AUTOSAR XML (schema 4-2-2)
package /UAES/ASW
  swc implementation Implementation: programming-language=C, sw-version=1.30.1, used-code-generator=Embedded Coder 7.1 (R2018b) 24-May-2018, vendor-id=0, behavior=InternalBehavior
    code-descriptors:
      code Code
        artifact-descriptors:
          short-label=IntLamp_Ctrl_c, category=SWSRC
          short-label=IntLamp_Ctrl_h, category=SWHDR
          short-label=rtwtypes_h, category=SWHDR
    resource consumption RsrcCons_IntLamp_Ctrl
package /UAES/ASW/SwComponentTypes
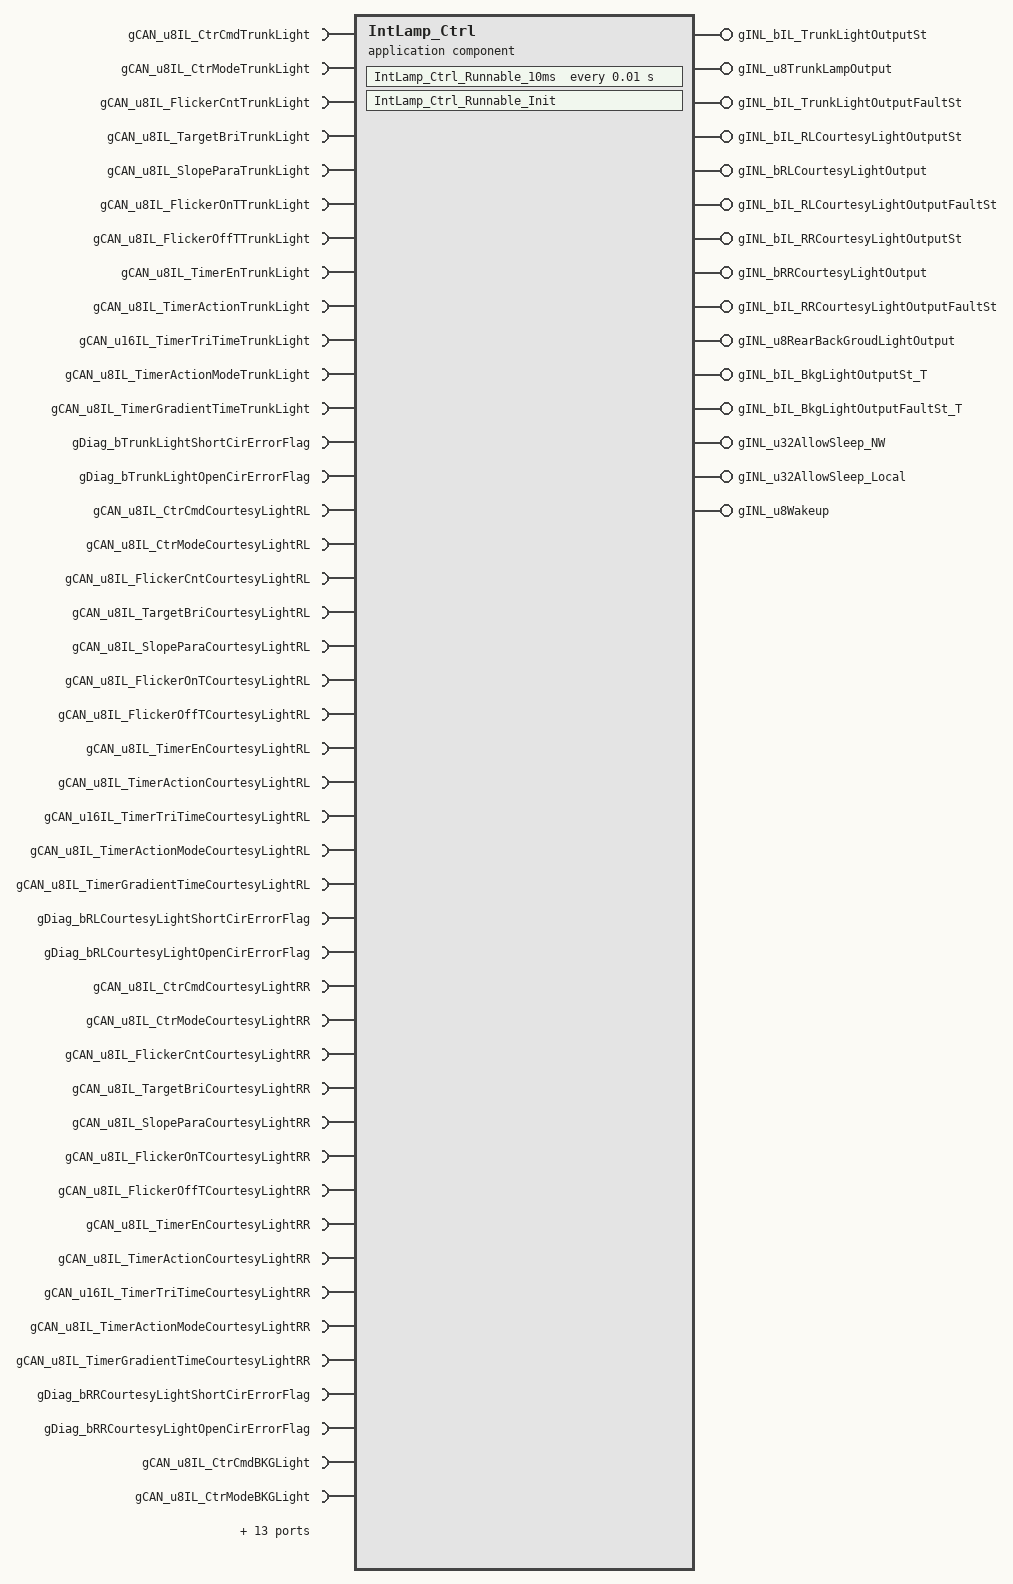
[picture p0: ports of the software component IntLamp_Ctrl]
  application sw component type IntLamp_Ctrl
    57 x require port:
      gCAN_u8IL_CtrCmdTrunkLight: nonqueued-receiver-com-spec{data-element=gCAN_u8IL_CtrCmdTrunkLight/Val, init-value=0}, required-interface=gCAN_u8IL_CtrCmdTrunkLight
      gCAN_u8IL_CtrModeTrunkLight: nonqueued-receiver-com-spec{data-element=gCAN_u8IL_CtrModeTrunkLight/Val, init-value=0}, required-interface=gCAN_u8IL_CtrModeTrunkLight
      gCAN_u8IL_FlickerCntTrunkLight: nonqueued-receiver-com-spec{data-element=gCAN_u8IL_FlickerCntTrunkLight/Val, init-value=0}, required-interface=gCAN_u8IL_FlickerCntTrunkLight
      gCAN_u8IL_TargetBriTrunkLight: nonqueued-receiver-com-spec{data-element=gCAN_u8IL_TargetBriTrunkLight/Val, init-value=0}, required-interface=gCAN_u8IL_TargetBriTrunkLight
      gCAN_u8IL_SlopeParaTrunkLight: nonqueued-receiver-com-spec{data-element=gCAN_u8IL_SlopeParaTrunkLight/Val, init-value=0}, required-interface=gCAN_u8IL_SlopeParaTrunkLight
      gCAN_u8IL_FlickerOnTTrunkLight: nonqueued-receiver-com-spec{data-element=gCAN_u8IL_FlickerOnTTrunkLight/Val, init-value=0}, required-interface=gCAN_u8IL_FlickerOnTTrunkLight
      gCAN_u8IL_FlickerOffTTrunkLight: nonqueued-receiver-com-spec{data-element=gCAN_u8IL_FlickerOffTTrunkLight/Val, init-value=0}, required-interface=gCAN_u8IL_FlickerOffTTrunkLight
      gCAN_u8IL_TimerEnTrunkLight: nonqueued-receiver-com-spec{data-element=gCAN_u8IL_TimerEnTrunkLight/Val, init-value=0}, required-interface=gCAN_u8IL_TimerEnTrunkLight
      gCAN_u8IL_TimerActionTrunkLight: nonqueued-receiver-com-spec{data-element=gCAN_u8IL_TimerActionTrunkLight/Val, init-value=0}, required-interface=gCAN_u8IL_TimerActionTrunkLight
      gCAN_u16IL_TimerTriTimeTrunkLight: nonqueued-receiver-com-spec{data-element=gCAN_u16IL_TimerTriTimeTrunkLight/Val, init-value=0}, required-interface=gCAN_u16IL_TimerTriTimeTrunkLight
      gCAN_u8IL_TimerActionModeTrunkLight: nonqueued-receiver-com-spec{data-element=gCAN_u8IL_TimerActionModeTrunkLight/Val, init-value=0}, required-interface=gCAN_u8IL_TimerActionModeTrunkLight
      gCAN_u8IL_TimerGradientTimeTrunkLight: nonqueued-receiver-com-spec{data-element=gCAN_u8IL_TimerGradientTimeTrunkLight/Val, init-value=0}, required-interface=gCAN_u8IL_TimerGradientTimeTrunkLight
      gDiag_bTrunkLightShortCirErrorFlag: nonqueued-receiver-com-spec{data-element=gDiag_bTrunkLightShortCirErrorFlag/Val, init-value=0}, required-interface=gDiag_bTrunkLightShortCirErrorFlag
      gDiag_bTrunkLightOpenCirErrorFlag: nonqueued-receiver-com-spec{data-element=gDiag_bTrunkLightOpenCirErrorFlag/Val, init-value=0}, required-interface=gDiag_bTrunkLightOpenCirErrorFlag
      gCAN_u8IL_CtrCmdCourtesyLightRL: nonqueued-receiver-com-spec{data-element=gCAN_u8IL_CtrCmdCourtesyLightRL/Val, init-value=0}, required-interface=gCAN_u8IL_CtrCmdCourtesyLightRL
      gCAN_u8IL_CtrModeCourtesyLightRL: nonqueued-receiver-com-spec{data-element=gCAN_u8IL_CtrModeCourtesyLightRL/Val, init-value=0}, required-interface=gCAN_u8IL_CtrModeCourtesyLightRL
      gCAN_u8IL_FlickerCntCourtesyLightRL: nonqueued-receiver-com-spec{data-element=gCAN_u8IL_FlickerCntCourtesyLightRL/Val, init-value=0}, required-interface=gCAN_u8IL_FlickerCntCourtesyLightRL
      gCAN_u8IL_TargetBriCourtesyLightRL: nonqueued-receiver-com-spec{data-element=gCAN_u8IL_TargetBriCourtesyLightRL/Val, init-value=0}, required-interface=gCAN_u8IL_TargetBriCourtesyLightRL
      gCAN_u8IL_SlopeParaCourtesyLightRL: nonqueued-receiver-com-spec{data-element=gCAN_u8IL_SlopeParaCourtesyLightRL/Val, init-value=0}, required-interface=gCAN_u8IL_SlopeParaCourtesyLightRL
      gCAN_u8IL_FlickerOnTCourtesyLightRL: nonqueued-receiver-com-spec{data-element=gCAN_u8IL_FlickerOnTCourtesyLightRL/Val, init-value=0}, required-interface=gCAN_u8IL_FlickerOnTCourtesyLightRL
      gCAN_u8IL_FlickerOffTCourtesyLightRL: nonqueued-receiver-com-spec{data-element=gCAN_u8IL_FlickerOffTCourtesyLightRL/Val, init-value=0}, required-interface=gCAN_u8IL_FlickerOffTCourtesyLightRL
      gCAN_u8IL_TimerEnCourtesyLightRL: nonqueued-receiver-com-spec{data-element=gCAN_u8IL_TimerEnCourtesyLightRL/Val, init-value=0}, required-interface=gCAN_u8IL_TimerEnCourtesyLightRL
      gCAN_u8IL_TimerActionCourtesyLightRL: nonqueued-receiver-com-spec{data-element=gCAN_u8IL_TimerActionCourtesyLightRL/Val, init-value=0}, required-interface=gCAN_u8IL_TimerActionCourtesyLightRL
      gCAN_u16IL_TimerTriTimeCourtesyLightRL: nonqueued-receiver-com-spec{data-element=gCAN_u16IL_TimerTriTimeCourtesyLightRL/Val, init-value=0}, required-interface=gCAN_u16IL_TimerTriTimeCourtesyLightRL
      gCAN_u8IL_TimerActionModeCourtesyLightRL: nonqueued-receiver-com-spec{data-element=gCAN_u8IL_TimerActionModeCourtesyLightRL/Val, init-value=0}, required-interface=gCAN_u8IL_TimerActionModeCourtesyLightRL
      gCAN_u8IL_TimerGradientTimeCourtesyLightRL: nonqueued-receiver-com-spec{data-element=gCAN_u8IL_TimerGradientTimeCourtesyLightRL/Val, init-value=0}, required-interface=gCAN_u8IL_TimerGradientTimeCourtesyLightRL
      gDiag_bRLCourtesyLightShortCirErrorFlag: nonqueued-receiver-com-spec{data-element=gDiag_bRLCourtesyLightShortCirErrorFlag/Val, init-value=0}, required-interface=gDiag_bRLCourtesyLightShortCirErrorFlag
      gDiag_bRLCourtesyLightOpenCirErrorFlag: nonqueued-receiver-com-spec{data-element=gDiag_bRLCourtesyLightOpenCirErrorFlag/Val, init-value=0}, required-interface=gDiag_bRLCourtesyLightOpenCirErrorFlag
      gCAN_u8IL_CtrCmdCourtesyLightRR: nonqueued-receiver-com-spec{data-element=gCAN_u8IL_CtrCmdCourtesyLightRR/Val, init-value=0}, required-interface=gCAN_u8IL_CtrCmdCourtesyLightRR
      gCAN_u8IL_CtrModeCourtesyLightRR: nonqueued-receiver-com-spec{data-element=gCAN_u8IL_CtrModeCourtesyLightRR/Val, init-value=0}, required-interface=gCAN_u8IL_CtrModeCourtesyLightRR
      gCAN_u8IL_FlickerCntCourtesyLightRR: nonqueued-receiver-com-spec{data-element=gCAN_u8IL_FlickerCntCourtesyLightRR/Val, init-value=0}, required-interface=gCAN_u8IL_FlickerCntCourtesyLightRR
      gCAN_u8IL_TargetBriCourtesyLightRR: nonqueued-receiver-com-spec{data-element=gCAN_u8IL_TargetBriCourtesyLightRR/Val, init-value=0}, required-interface=gCAN_u8IL_TargetBriCourtesyLightRR
      gCAN_u8IL_SlopeParaCourtesyLightRR: nonqueued-receiver-com-spec{data-element=gCAN_u8IL_SlopeParaCourtesyLightRR/Val, init-value=0}, required-interface=gCAN_u8IL_SlopeParaCourtesyLightRR
      gCAN_u8IL_FlickerOnTCourtesyLightRR: nonqueued-receiver-com-spec{data-element=gCAN_u8IL_FlickerOnTCourtesyLightRR/Val, init-value=0}, required-interface=gCAN_u8IL_FlickerOnTCourtesyLightRR
      gCAN_u8IL_FlickerOffTCourtesyLightRR: nonqueued-receiver-com-spec{data-element=gCAN_u8IL_FlickerOffTCourtesyLightRR/Val, init-value=0}, required-interface=gCAN_u8IL_FlickerOffTCourtesyLightRR
      gCAN_u8IL_TimerEnCourtesyLightRR: nonqueued-receiver-com-spec{data-element=gCAN_u8IL_TimerEnCourtesyLightRR/Val, init-value=0}, required-interface=gCAN_u8IL_TimerEnCourtesyLightRR
      gCAN_u8IL_TimerActionCourtesyLightRR: nonqueued-receiver-com-spec{data-element=gCAN_u8IL_TimerActionCourtesyLightRR/Val, init-value=0}, required-interface=gCAN_u8IL_TimerActionCourtesyLightRR
      gCAN_u16IL_TimerTriTimeCourtesyLightRR: nonqueued-receiver-com-spec{data-element=gCAN_u16IL_TimerTriTimeCourtesyLightRR/Val, init-value=0}, required-interface=gCAN_u16IL_TimerTriTimeCourtesyLightRR
      gCAN_u8IL_TimerActionModeCourtesyLightRR: nonqueued-receiver-com-spec{data-element=gCAN_u8IL_TimerActionModeCourtesyLightRR/Val, init-value=0}, required-interface=gCAN_u8IL_TimerActionModeCourtesyLightRR
      gCAN_u8IL_TimerGradientTimeCourtesyLightRR: nonqueued-receiver-com-spec{data-element=gCAN_u8IL_TimerGradientTimeCourtesyLightRR/Val, init-value=0}, required-interface=gCAN_u8IL_TimerGradientTimeCourtesyLightRR
      gDiag_bRRCourtesyLightShortCirErrorFlag: nonqueued-receiver-com-spec{data-element=gDiag_bRRCourtesyLightShortCirErrorFlag/Val, init-value=0}, required-interface=gDiag_bRRCourtesyLightShortCirErrorFlag
      gDiag_bRRCourtesyLightOpenCirErrorFlag: nonqueued-receiver-com-spec{data-element=gDiag_bRRCourtesyLightOpenCirErrorFlag/Val, init-value=0}, required-interface=gDiag_bRRCourtesyLightOpenCirErrorFlag
      gCAN_u8IL_CtrCmdBKGLight: nonqueued-receiver-com-spec{data-element=gCAN_u8IL_CtrCmdBKGLight/Val, init-value=0}, required-interface=gCAN_u8IL_CtrCmdBKGLight
      gCAN_u8IL_CtrModeBKGLight: nonqueued-receiver-com-spec{data-element=gCAN_u8IL_CtrModeBKGLight/Val, init-value=0}, required-interface=gCAN_u8IL_CtrModeBKGLight
      gCAN_u8IL_FlickerCntBKGLight: nonqueued-receiver-com-spec{data-element=gCAN_u8IL_FlickerCntBKGLight/Val, init-value=0}, required-interface=gCAN_u8IL_FlickerCntBKGLight
      gCAN_u8IL_TargetBriBKGLight: nonqueued-receiver-com-spec{data-element=gCAN_u8IL_TargetBriBKGLight/Val, init-value=0}, required-interface=gCAN_u8IL_TargetBriBKGLight
      gCAN_u8IL_SlopeParaBKGLight: nonqueued-receiver-com-spec{data-element=gCAN_u8IL_SlopeParaBKGLight/Val, init-value=0}, required-interface=gCAN_u8IL_SlopeParaBKGLight
      gCAN_u8IL_FlickerOnTBKGLight: nonqueued-receiver-com-spec{data-element=gCAN_u8IL_FlickerOnTBKGLight/Val, init-value=0}, required-interface=gCAN_u8IL_FlickerOnTBKGLight
      gCAN_u8IL_FlickerOffTBKGLight: nonqueued-receiver-com-spec{data-element=gCAN_u8IL_FlickerOffTBKGLight/Val, init-value=0}, required-interface=gCAN_u8IL_FlickerOffTBKGLight
      gCAN_u8IL_TimerEnBKGLight: nonqueued-receiver-com-spec{data-element=gCAN_u8IL_TimerEnBKGLight/Val, init-value=0}, required-interface=gCAN_u8IL_TimerEnBKGLight
      gCAN_u8IL_TimerActionBKGLight: nonqueued-receiver-com-spec{data-element=gCAN_u8IL_TimerActionBKGLight/Val, init-value=0}, required-interface=gCAN_u8IL_TimerActionBKGLight
      gCAN_u16IL_TimerTriTimeBKGLight: nonqueued-receiver-com-spec{data-element=gCAN_u16IL_TimerTriTimeBKGLight/Val, init-value=0}, required-interface=gCAN_u16IL_TimerTriTimeBKGLight
      gCAN_u8IL_TimerActionModeBKGLight: nonqueued-receiver-com-spec{data-element=gCAN_u8IL_TimerActionModeBKGLight/Val, init-value=0}, required-interface=gCAN_u8IL_TimerActionModeBKGLight
      gCAN_u8IL_TimerGradientTimeBKGLight: nonqueued-receiver-com-spec{data-element=gCAN_u8IL_TimerGradientTimeBKGLight/Val, init-value=0}, required-interface=gCAN_u8IL_TimerGradientTimeBKGLight
      gDiag_bReBkgLightPowerShortCirErrorFlag: nonqueued-receiver-com-spec{data-element=gDiag_bReBkgLightPowerShortCirErrorFlag/Val, init-value=0}, required-interface=gDiag_bReBkgLightPowerShortCirErrorFlag
      gDiag_bReBkgLightPowerOpenCirErrorFlag: nonqueued-receiver-com-spec{data-element=gDiag_bReBkgLightPowerOpenCirErrorFlag/Val, init-value=0}, required-interface=gDiag_bReBkgLightPowerOpenCirErrorFlag
      gASI_bIL_CtrCmdTrunkLight_TimeOut: nonqueued-receiver-com-spec{data-element=gASI_bIL_CtrCmdTrunkLight_TimeOut/Val, init-value=0}, required-interface=gASI_bIL_CtrCmdTrunkLight_TimeOut
    15 x provide port:
      gINL_bIL_TrunkLightOutputSt: nonqueued-sender-com-spec{data-element=gINL_bIL_TrunkLightOutputSt/Val, init-value=0}, provided-interface=gINL_bIL_TrunkLightOutputSt
      gINL_u8TrunkLampOutput: nonqueued-sender-com-spec{data-element=gINL_u8TrunkLampOutput/Val, init-value=0}, provided-interface=gINL_u8TrunkLampOutput
      gINL_bIL_TrunkLightOutputFaultSt: nonqueued-sender-com-spec{data-element=gINL_bIL_TrunkLightOutputFaultSt/Val, init-value=0}, provided-interface=gINL_bIL_TrunkLightOutputFaultSt
      gINL_bIL_RLCourtesyLightOutputSt: nonqueued-sender-com-spec{data-element=gINL_bIL_RLCourtesyLightOutputSt/Val, init-value=0}, provided-interface=gINL_bIL_RLCourtesyLightOutputSt
      gINL_bRLCourtesyLightOutput: nonqueued-sender-com-spec{data-element=gINL_bRLCourtesyLightOutput/Val, init-value=0}, provided-interface=gINL_bRLCourtesyLightOutput
      gINL_bIL_RLCourtesyLightOutputFaultSt: nonqueued-sender-com-spec{data-element=gINL_bIL_RLCourtesyLightOutputFaultSt/Val, init-value=0}, provided-interface=gINL_bIL_RLCourtesyLightOutputFaultSt
      gINL_bIL_RRCourtesyLightOutputSt: nonqueued-sender-com-spec{data-element=gINL_bIL_RRCourtesyLightOutputSt/Val, init-value=0}, provided-interface=gINL_bIL_RRCourtesyLightOutputSt
      gINL_bRRCourtesyLightOutput: nonqueued-sender-com-spec{data-element=gINL_bRRCourtesyLightOutput/Val, init-value=0}, provided-interface=gINL_bRRCourtesyLightOutput
      gINL_bIL_RRCourtesyLightOutputFaultSt: nonqueued-sender-com-spec{data-element=gINL_bIL_RRCourtesyLightOutputFaultSt/Val, init-value=0}, provided-interface=gINL_bIL_RRCourtesyLightOutputFaultSt
      gINL_u8RearBackGroudLightOutput: nonqueued-sender-com-spec{data-element=gINL_u8RearBackGroudLightOutput/Val, init-value=0}, provided-interface=gINL_u8RearBackGroudLightOutput
      gINL_bIL_BkgLightOutputSt_T: nonqueued-sender-com-spec{data-element=gINL_bIL_BkgLightOutputSt_T/Val, init-value=0}, provided-interface=gINL_bIL_BkgLightOutputSt_T
      gINL_bIL_BkgLightOutputFaultSt_T: nonqueued-sender-com-spec{data-element=gINL_bIL_BkgLightOutputFaultSt_T/Val, init-value=0}, provided-interface=gINL_bIL_BkgLightOutputFaultSt_T
      gINL_u32AllowSleep_NW: nonqueued-sender-com-spec{data-element=gINL_u32AllowSleep_NW/Val, init-value=0}, provided-interface=gINL_u32AllowSleep_NW
      gINL_u32AllowSleep_Local: nonqueued-sender-com-spec{data-element=gINL_u32AllowSleep_Local/Val, init-value=0}, provided-interface=gINL_u32AllowSleep_Local
      gINL_u8Wakeup: nonqueued-sender-com-spec{data-element=gINL_u8Wakeup/Val, init-value=0}, provided-interface=gINL_u8Wakeup
    behavior InternalBehavior: handle-termination-and-restart=NO-SUPPORT
      init event IntLamp_Ctrl_InitEvent: start-on-event=IntLamp_Ctrl_Runnable_Init
      timing event TMT_IntLamp_Ctrl_Runnable_10ms: start-on-event=IntLamp_Ctrl_Runnable_10ms, period=0.01
      runnable IntLamp_Ctrl_Runnable_Init
      runnable IntLamp_Ctrl_Runnable_10ms
        data-receive-point-by-arguments:
          57 x access:
            IN_gASI_bIL_CtrCmdTrunkLight_TimeOut_Val: accessed-variable=gASI_bIL_CtrCmdTrunkLight_TimeOut.Val
            IN_gCAN_u16IL_TimerTriTimeBKGLight_Val: accessed-variable=gCAN_u16IL_TimerTriTimeBKGLight.Val
            IN_gCAN_u16IL_TimerTriTimeCourtesyLightRL_Val: accessed-variable=gCAN_u16IL_TimerTriTimeCourtesyLightRL.Val
            IN_gCAN_u16IL_TimerTriTimeCourtesyLightRR_Val: accessed-variable=gCAN_u16IL_TimerTriTimeCourtesyLightRR.Val
            IN_gCAN_u16IL_TimerTriTimeTrunkLight_Val: accessed-variable=gCAN_u16IL_TimerTriTimeTrunkLight.Val
            IN_gCAN_u8IL_CtrCmdBKGLight_Val: accessed-variable=gCAN_u8IL_CtrCmdBKGLight.Val
            IN_gCAN_u8IL_CtrCmdCourtesyLightRL_Val: accessed-variable=gCAN_u8IL_CtrCmdCourtesyLightRL.Val
            IN_gCAN_u8IL_CtrCmdCourtesyLightRR_Val: accessed-variable=gCAN_u8IL_CtrCmdCourtesyLightRR.Val
            IN_gCAN_u8IL_CtrCmdTrunkLight_Val: accessed-variable=gCAN_u8IL_CtrCmdTrunkLight.Val
            IN_gCAN_u8IL_CtrModeBKGLight_Val: accessed-variable=gCAN_u8IL_CtrModeBKGLight.Val
            IN_gCAN_u8IL_CtrModeCourtesyLightRL_Val: accessed-variable=gCAN_u8IL_CtrModeCourtesyLightRL.Val
            IN_gCAN_u8IL_CtrModeCourtesyLightRR_Val: accessed-variable=gCAN_u8IL_CtrModeCourtesyLightRR.Val
            IN_gCAN_u8IL_CtrModeTrunkLight_Val: accessed-variable=gCAN_u8IL_CtrModeTrunkLight.Val
            IN_gCAN_u8IL_FlickerCntBKGLight_Val: accessed-variable=gCAN_u8IL_FlickerCntBKGLight.Val
            IN_gCAN_u8IL_FlickerCntCourtesyLightRL_Val: accessed-variable=gCAN_u8IL_FlickerCntCourtesyLightRL.Val
            IN_gCAN_u8IL_FlickerCntCourtesyLightRR_Val: accessed-variable=gCAN_u8IL_FlickerCntCourtesyLightRR.Val
            IN_gCAN_u8IL_FlickerCntTrunkLight_Val: accessed-variable=gCAN_u8IL_FlickerCntTrunkLight.Val
            IN_gCAN_u8IL_FlickerOffTBKGLight_Val: accessed-variable=gCAN_u8IL_FlickerOffTBKGLight.Val
            IN_gCAN_u8IL_FlickerOffTCourtesyLightRL_Val: accessed-variable=gCAN_u8IL_FlickerOffTCourtesyLightRL.Val
            IN_gCAN_u8IL_FlickerOffTCourtesyLightRR_Val: accessed-variable=gCAN_u8IL_FlickerOffTCourtesyLightRR.Val
            IN_gCAN_u8IL_FlickerOffTTrunkLight_Val: accessed-variable=gCAN_u8IL_FlickerOffTTrunkLight.Val
            IN_gCAN_u8IL_FlickerOnTBKGLight_Val: accessed-variable=gCAN_u8IL_FlickerOnTBKGLight.Val
            IN_gCAN_u8IL_FlickerOnTCourtesyLightRL_Val: accessed-variable=gCAN_u8IL_FlickerOnTCourtesyLightRL.Val
            IN_gCAN_u8IL_FlickerOnTCourtesyLightRR_Val: accessed-variable=gCAN_u8IL_FlickerOnTCourtesyLightRR.Val
            IN_gCAN_u8IL_FlickerOnTTrunkLight_Val: accessed-variable=gCAN_u8IL_FlickerOnTTrunkLight.Val
            IN_gCAN_u8IL_SlopeParaBKGLight_Val: accessed-variable=gCAN_u8IL_SlopeParaBKGLight.Val
            IN_gCAN_u8IL_SlopeParaCourtesyLightRL_Val: accessed-variable=gCAN_u8IL_SlopeParaCourtesyLightRL.Val
            IN_gCAN_u8IL_SlopeParaCourtesyLightRR_Val: accessed-variable=gCAN_u8IL_SlopeParaCourtesyLightRR.Val
            IN_gCAN_u8IL_SlopeParaTrunkLight_Val: accessed-variable=gCAN_u8IL_SlopeParaTrunkLight.Val
            IN_gCAN_u8IL_TargetBriBKGLight_Val: accessed-variable=gCAN_u8IL_TargetBriBKGLight.Val
            IN_gCAN_u8IL_TargetBriCourtesyLightRL_Val: accessed-variable=gCAN_u8IL_TargetBriCourtesyLightRL.Val
            IN_gCAN_u8IL_TargetBriCourtesyLightRR_Val: accessed-variable=gCAN_u8IL_TargetBriCourtesyLightRR.Val
            IN_gCAN_u8IL_TargetBriTrunkLight_Val: accessed-variable=gCAN_u8IL_TargetBriTrunkLight.Val
            IN_gCAN_u8IL_TimerActionBKGLight_Val: accessed-variable=gCAN_u8IL_TimerActionBKGLight.Val
            IN_gCAN_u8IL_TimerActionCourtesyLightRL_Val: accessed-variable=gCAN_u8IL_TimerActionCourtesyLightRL.Val
            IN_gCAN_u8IL_TimerActionCourtesyLightRR_Val: accessed-variable=gCAN_u8IL_TimerActionCourtesyLightRR.Val
            IN_gCAN_u8IL_TimerActionModeBKGLight_Val: accessed-variable=gCAN_u8IL_TimerActionModeBKGLight.Val
            IN_gCAN_u8IL_TimerActionModeCourtesyLightRL_Val: accessed-variable=gCAN_u8IL_TimerActionModeCourtesyLightRL.Val
            IN_gCAN_u8IL_TimerActionModeCourtesyLightRR_Val: accessed-variable=gCAN_u8IL_TimerActionModeCourtesyLightRR.Val
            IN_gCAN_u8IL_TimerActionModeTrunkLight_Val: accessed-variable=gCAN_u8IL_TimerActionModeTrunkLight.Val
            IN_gCAN_u8IL_TimerActionTrunkLight_Val: accessed-variable=gCAN_u8IL_TimerActionTrunkLight.Val
            IN_gCAN_u8IL_TimerEnBKGLight_Val: accessed-variable=gCAN_u8IL_TimerEnBKGLight.Val
            IN_gCAN_u8IL_TimerEnCourtesyLightRL_Val: accessed-variable=gCAN_u8IL_TimerEnCourtesyLightRL.Val
            IN_gCAN_u8IL_TimerEnCourtesyLightRR_Val: accessed-variable=gCAN_u8IL_TimerEnCourtesyLightRR.Val
            IN_gCAN_u8IL_TimerEnTrunkLight_Val: accessed-variable=gCAN_u8IL_TimerEnTrunkLight.Val
            IN_gCAN_u8IL_TimerGradientTimeBKGLight_Val: accessed-variable=gCAN_u8IL_TimerGradientTimeBKGLight.Val
            IN_gCAN_u8IL_TimerGradientTimeCourtesyLightRL_Val: accessed-variable=gCAN_u8IL_TimerGradientTimeCourtesyLightRL.Val
            IN_gCAN_u8IL_TimerGradientTimeCourtesyLightRR_Val: accessed-variable=gCAN_u8IL_TimerGradientTimeCourtesyLightRR.Val
            IN_gCAN_u8IL_TimerGradientTimeTrunkLight_Val: accessed-variable=gCAN_u8IL_TimerGradientTimeTrunkLight.Val
            IN_gDiag_bRLCourtesyLightOpenCirErrorFlag_Val: accessed-variable=gDiag_bRLCourtesyLightOpenCirErrorFlag.Val
            IN_gDiag_bRLCourtesyLightShortCirErrorFlag_Val: accessed-variable=gDiag_bRLCourtesyLightShortCirErrorFlag.Val
            IN_gDiag_bRRCourtesyLightOpenCirErrorFlag_Val: accessed-variable=gDiag_bRRCourtesyLightOpenCirErrorFlag.Val
            IN_gDiag_bRRCourtesyLightShortCirErrorFlag_Val: accessed-variable=gDiag_bRRCourtesyLightShortCirErrorFlag.Val
            IN_gDiag_bReBkgLightPowerOpenCirErrorFlag_Val: accessed-variable=gDiag_bReBkgLightPowerOpenCirErrorFlag.Val
            IN_gDiag_bReBkgLightPowerShortCirErrorFlag_Val: accessed-variable=gDiag_bReBkgLightPowerShortCirErrorFlag.Val
            IN_gDiag_bTrunkLightOpenCirErrorFlag_Val: accessed-variable=gDiag_bTrunkLightOpenCirErrorFlag.Val
            IN_gDiag_bTrunkLightShortCirErrorFlag_Val: accessed-variable=gDiag_bTrunkLightShortCirErrorFlag.Val
        data-send-points:
          15 x access:
            OUT_gINL_bIL_TrunkLightOutputSt_Val: accessed-variable=gINL_bIL_TrunkLightOutputSt.Val
            OUT_gINL_u8TrunkLampOutput_Val: accessed-variable=gINL_u8TrunkLampOutput.Val
            OUT_gINL_bIL_TrunkLightOutputFaultSt_Val: accessed-variable=gINL_bIL_TrunkLightOutputFaultSt.Val
            OUT_gINL_bIL_RLCourtesyLightOutputSt_Val: accessed-variable=gINL_bIL_RLCourtesyLightOutputSt.Val
            OUT_gINL_bRLCourtesyLightOutput_Val: accessed-variable=gINL_bRLCourtesyLightOutput.Val
            OUT_gINL_bIL_RLCourtesyLightOutputFaultSt_Val: accessed-variable=gINL_bIL_RLCourtesyLightOutputFaultSt.Val
            OUT_gINL_bIL_RRCourtesyLightOutputSt_Val: accessed-variable=gINL_bIL_RRCourtesyLightOutputSt.Val
            OUT_gINL_bRRCourtesyLightOutput_Val: accessed-variable=gINL_bRRCourtesyLightOutput.Val
            OUT_gINL_bIL_RRCourtesyLightOutputFaultSt_Val: accessed-variable=gINL_bIL_RRCourtesyLightOutputFaultSt.Val
            OUT_gINL_u8RearBackGroudLightOutput_Val: accessed-variable=gINL_u8RearBackGroudLightOutput.Val
            OUT_gINL_bIL_BkgLightOutputSt_T_Val: accessed-variable=gINL_bIL_BkgLightOutputSt_T.Val
            OUT_gINL_bIL_BkgLightOutputFaultSt_T_Val: accessed-variable=gINL_bIL_BkgLightOutputFaultSt_T.Val
            OUT_gINL_u32AllowSleep_NW_Val: accessed-variable=gINL_u32AllowSleep_NW.Val
            OUT_gINL_u32AllowSleep_Local_Val: accessed-variable=gINL_u32AllowSleep_Local.Val
            OUT_gINL_u8Wakeup_Val: accessed-variable=gINL_u8Wakeup.Val
package /UAES/ASW/PortInterfaces
  72 x sender receiver interface:
    gCAN_u8IL_CtrCmdTrunkLight
      data Val: category=VALUE, sw-calibration-access=READ-ONLY, type=uint8
    gCAN_u8IL_CtrModeTrunkLight
      data Val: category=VALUE, sw-calibration-access=READ-ONLY, type=uint8
    gCAN_u8IL_FlickerCntTrunkLight
      data Val: category=VALUE, sw-calibration-access=READ-ONLY, type=uint8
    gCAN_u8IL_TargetBriTrunkLight
      data Val: category=VALUE, sw-calibration-access=READ-ONLY, type=uint8
    gCAN_u8IL_SlopeParaTrunkLight
      data Val: category=VALUE, sw-calibration-access=READ-ONLY, type=uint8
    gCAN_u8IL_FlickerOnTTrunkLight
      data Val: category=VALUE, sw-calibration-access=READ-ONLY, type=uint8
    gCAN_u8IL_FlickerOffTTrunkLight
      data Val: category=VALUE, sw-calibration-access=READ-ONLY, type=uint8
    gCAN_u8IL_TimerEnTrunkLight
      data Val: category=VALUE, sw-calibration-access=READ-ONLY, type=uint8
    gCAN_u8IL_TimerActionTrunkLight
      data Val: category=VALUE, sw-calibration-access=READ-ONLY, type=uint8
    gCAN_u16IL_TimerTriTimeTrunkLight
      data Val: category=VALUE, sw-calibration-access=READ-ONLY, type=uint16
    gCAN_u8IL_TimerActionModeTrunkLight
      data Val: category=VALUE, sw-calibration-access=READ-ONLY, type=uint8
    gCAN_u8IL_TimerGradientTimeTrunkLight
      data Val: category=VALUE, sw-calibration-access=READ-ONLY, type=uint8
    gDiag_bTrunkLightShortCirErrorFlag
      data Val: category=VALUE, sw-calibration-access=READ-ONLY, type=boolean
    gDiag_bTrunkLightOpenCirErrorFlag
      data Val: category=VALUE, sw-calibration-access=READ-ONLY, type=boolean
    gCAN_u8IL_CtrCmdCourtesyLightRL
      data Val: category=VALUE, sw-calibration-access=READ-ONLY, type=uint8
    gCAN_u8IL_CtrModeCourtesyLightRL
      data Val: category=VALUE, sw-calibration-access=READ-ONLY, type=uint8
    gCAN_u8IL_FlickerCntCourtesyLightRL
      data Val: category=VALUE, sw-calibration-access=READ-ONLY, type=uint8
    gCAN_u8IL_TargetBriCourtesyLightRL
      data Val: category=VALUE, sw-calibration-access=READ-ONLY, type=uint8
    gCAN_u8IL_SlopeParaCourtesyLightRL
      data Val: category=VALUE, sw-calibration-access=READ-ONLY, type=uint8
    gCAN_u8IL_FlickerOnTCourtesyLightRL
      data Val: category=VALUE, sw-calibration-access=READ-ONLY, type=uint8
    gCAN_u8IL_FlickerOffTCourtesyLightRL
      data Val: category=VALUE, sw-calibration-access=READ-ONLY, type=uint8
    gCAN_u8IL_TimerEnCourtesyLightRL
      data Val: category=VALUE, sw-calibration-access=READ-ONLY, type=uint8
    gCAN_u8IL_TimerActionCourtesyLightRL
      data Val: category=VALUE, sw-calibration-access=READ-ONLY, type=uint8
    gCAN_u16IL_TimerTriTimeCourtesyLightRL
      data Val: category=VALUE, sw-calibration-access=READ-ONLY, type=uint16
    gCAN_u8IL_TimerActionModeCourtesyLightRL
      data Val: category=VALUE, sw-calibration-access=READ-ONLY, type=uint8
    gCAN_u8IL_TimerGradientTimeCourtesyLightRL
      data Val: category=VALUE, sw-calibration-access=READ-ONLY, type=uint8
    gDiag_bRLCourtesyLightShortCirErrorFlag
      data Val: category=VALUE, sw-calibration-access=READ-ONLY, type=boolean
    gDiag_bRLCourtesyLightOpenCirErrorFlag
      data Val: category=VALUE, sw-calibration-access=READ-ONLY, type=boolean
    gCAN_u8IL_CtrCmdCourtesyLightRR
      data Val: category=VALUE, sw-calibration-access=READ-ONLY, type=uint8
    gCAN_u8IL_CtrModeCourtesyLightRR
      data Val: category=VALUE, sw-calibration-access=READ-ONLY, type=uint8
    gCAN_u8IL_FlickerCntCourtesyLightRR
      data Val: category=VALUE, sw-calibration-access=READ-ONLY, type=uint8
    gCAN_u8IL_TargetBriCourtesyLightRR
      data Val: category=VALUE, sw-calibration-access=READ-ONLY, type=uint8
    gCAN_u8IL_SlopeParaCourtesyLightRR
      data Val: category=VALUE, sw-calibration-access=READ-ONLY, type=uint8
    gCAN_u8IL_FlickerOnTCourtesyLightRR
      data Val: category=VALUE, sw-calibration-access=READ-ONLY, type=uint8
    gCAN_u8IL_FlickerOffTCourtesyLightRR
      data Val: category=VALUE, sw-calibration-access=READ-ONLY, type=uint8
    gCAN_u8IL_TimerEnCourtesyLightRR
      data Val: category=VALUE, sw-calibration-access=READ-ONLY, type=uint8
    gCAN_u8IL_TimerActionCourtesyLightRR
      data Val: category=VALUE, sw-calibration-access=READ-ONLY, type=uint8
    gCAN_u16IL_TimerTriTimeCourtesyLightRR
      data Val: category=VALUE, sw-calibration-access=READ-ONLY, type=uint16
    gCAN_u8IL_TimerActionModeCourtesyLightRR
      data Val: category=VALUE, sw-calibration-access=READ-ONLY, type=uint8
    gCAN_u8IL_TimerGradientTimeCourtesyLightRR
      data Val: category=VALUE, sw-calibration-access=READ-ONLY, type=uint8
    gDiag_bRRCourtesyLightShortCirErrorFlag
      data Val: category=VALUE, sw-calibration-access=READ-ONLY, type=boolean
    gDiag_bRRCourtesyLightOpenCirErrorFlag
      data Val: category=VALUE, sw-calibration-access=READ-ONLY, type=boolean
    gCAN_u8IL_CtrCmdBKGLight
      data Val: category=VALUE, sw-calibration-access=READ-ONLY, type=uint8
    gCAN_u8IL_CtrModeBKGLight
      data Val: category=VALUE, sw-calibration-access=READ-ONLY, type=uint8
    gCAN_u8IL_FlickerCntBKGLight
      data Val: category=VALUE, sw-calibration-access=READ-ONLY, type=uint8
    gCAN_u8IL_TargetBriBKGLight
      data Val: category=VALUE, sw-calibration-access=READ-ONLY, type=uint8
    gCAN_u8IL_SlopeParaBKGLight
      data Val: category=VALUE, sw-calibration-access=READ-ONLY, type=uint8
    gCAN_u8IL_FlickerOnTBKGLight
      data Val: category=VALUE, sw-calibration-access=READ-ONLY, type=uint8
    gCAN_u8IL_FlickerOffTBKGLight
      data Val: category=VALUE, sw-calibration-access=READ-ONLY, type=uint8
    gCAN_u8IL_TimerEnBKGLight
      data Val: category=VALUE, sw-calibration-access=READ-ONLY, type=uint8
    gCAN_u8IL_TimerActionBKGLight
      data Val: category=VALUE, sw-calibration-access=READ-ONLY, type=uint8
    gCAN_u16IL_TimerTriTimeBKGLight
      data Val: category=VALUE, sw-calibration-access=READ-ONLY, type=uint16
    gCAN_u8IL_TimerActionModeBKGLight
      data Val: category=VALUE, sw-calibration-access=READ-ONLY, type=uint8
    gCAN_u8IL_TimerGradientTimeBKGLight
      data Val: category=VALUE, sw-calibration-access=READ-ONLY, type=uint8
    gDiag_bReBkgLightPowerShortCirErrorFlag
      data Val: category=VALUE, sw-calibration-access=READ-ONLY, type=boolean
    gDiag_bReBkgLightPowerOpenCirErrorFlag
      data Val: category=VALUE, sw-calibration-access=READ-ONLY, type=boolean
    gASI_bIL_CtrCmdTrunkLight_TimeOut
      data Val: category=VALUE, sw-calibration-access=READ-ONLY, type=boolean
    gINL_bIL_TrunkLightOutputSt
      data Val: category=VALUE, sw-calibration-access=READ-ONLY, type=boolean
    gINL_u8TrunkLampOutput
      data Val: category=VALUE, sw-calibration-access=READ-ONLY, type=uint8
    gINL_bIL_TrunkLightOutputFaultSt
      data Val: category=VALUE, sw-calibration-access=READ-ONLY, type=boolean
    gINL_bIL_RLCourtesyLightOutputSt
      data Val: category=VALUE, sw-calibration-access=READ-ONLY, type=boolean
    gINL_bRLCourtesyLightOutput
      data Val: category=VALUE, sw-calibration-access=READ-ONLY, type=boolean
    gINL_bIL_RLCourtesyLightOutputFaultSt
      data Val: category=VALUE, sw-calibration-access=READ-ONLY, type=boolean
    gINL_bIL_RRCourtesyLightOutputSt
      data Val: category=VALUE, sw-calibration-access=READ-ONLY, type=boolean
    gINL_bRRCourtesyLightOutput
      data Val: category=VALUE, sw-calibration-access=READ-ONLY, type=boolean
    gINL_bIL_RRCourtesyLightOutputFaultSt
      data Val: category=VALUE, sw-calibration-access=READ-ONLY, type=boolean
    gINL_u8RearBackGroudLightOutput
      data Val: category=VALUE, sw-calibration-access=READ-ONLY, type=uint8
    gINL_bIL_BkgLightOutputSt_T
      data Val: category=VALUE, sw-calibration-access=READ-ONLY, type=boolean
    gINL_bIL_BkgLightOutputFaultSt_T
      data Val: category=VALUE, sw-calibration-access=READ-ONLY, type=boolean
    gINL_u32AllowSleep_NW
      data Val: category=VALUE, sw-calibration-access=READ-ONLY, type=uint32
    gINL_u32AllowSleep_Local
      data Val: category=VALUE, sw-calibration-access=READ-ONLY, type=uint32
    gINL_u8Wakeup
      data Val: category=VALUE, sw-calibration-access=READ-ONLY, type=uint8
